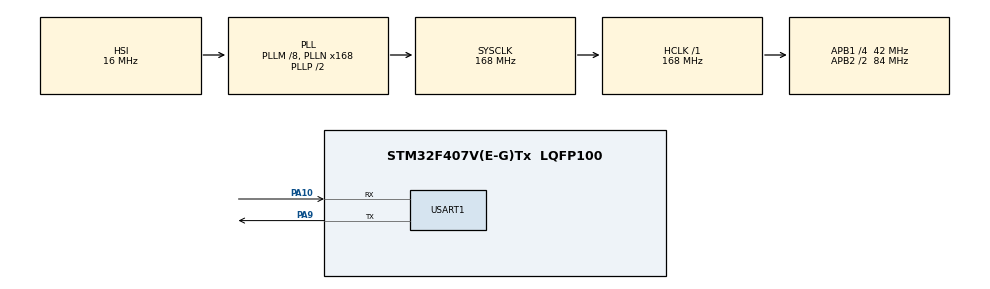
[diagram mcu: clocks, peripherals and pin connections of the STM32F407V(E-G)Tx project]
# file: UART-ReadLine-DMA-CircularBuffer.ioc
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Dma.Request0=USART1_RX
Dma.USART1_RX.0.Direction=DMA_PERIPH_TO_MEMORY
Dma.USART1_RX.0.FIFOMode=DMA_FIFOMODE_DISABLE
Dma.USART1_RX.0.Instance=DMA2_Stream2
Dma.USART1_RX.0.MemDataAlignment=DMA_MDATAALIGN_BYTE
Dma.USART1_RX.0.MemInc=DMA_MINC_ENABLE
Dma.USART1_RX.0.Mode=DMA_NORMAL
Dma.USART1_RX.0.PeriphDataAlignment=DMA_PDATAALIGN_BYTE
Dma.USART1_RX.0.PeriphInc=DMA_PINC_DISABLE
Dma.USART1_RX.0.Priority=DMA_PRIORITY_LOW
Mcu.Family=STM32F4
Mcu.Name=STM32F407V(E-G)Tx
Mcu.Package=LQFP100
NVIC.DMA2_Stream2_IRQn=true\:0\:0\:false\:false\:true\:false\:true
NVIC.PriorityGroup=NVIC_PRIORITYGROUP_4
NVIC.USART1_IRQn=true\:0\:0\:false\:false\:true\:true\:true
PA10.Mode=Asynchronous
PA10.Signal=USART1_RX
PA9.Mode=Asynchronous
PA9.Signal=USART1_TX
ProjectManager.HeapSize=0x200
ProjectManager.StackSize=0x400
ProjectManager.TargetToolchain=MDK-ARM V5.27
RCC.48MHZClocksFreq_Value=84000000
RCC.AHBFreq_Value=168000000
RCC.APB1CLKDivider=RCC_HCLK_DIV4
RCC.APB1Freq_Value=42000000
RCC.APB1TimFreq_Value=84000000
RCC.APB2CLKDivider=RCC_HCLK_DIV2
RCC.APB2Freq_Value=84000000
RCC.APB2TimFreq_Value=168000000
RCC.CortexFreq_Value=168000000
RCC.HCLKFreq_Value=168000000
RCC.HSE_VALUE=25000000
RCC.HSI_VALUE=16000000
RCC.LSE_VALUE=32768
RCC.PLLM=8
RCC.PLLN=168
RCC.SYSCLKFreq_VALUE=168000000
RCC.SYSCLKSource=RCC_SYSCLKSOURCE_PLLCLK
RCC.VCOOutputFreq_Value=336000000
USART1.VirtualMode=VM_ASYNC
board=custom

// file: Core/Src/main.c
/* USER CODE BEGIN Header */
/**
  ******************************************************************************
  * @file           : main.c
  * @brief          : Main program body
  ******************************************************************************
  * @attention
  *
  * <h2><center>&copy; Copyright (c) 2023 STMicroelectronics.
  * All rights reserved.</center></h2>
  *
  * This software component is licensed by ST under BSD 3-Clause license,
  * the "License"; You may not use this file except in compliance with the
  * License. You may obtain a copy of the License at:
  *                        opensource.org/licenses/BSD-3-Clause
  *
  ******************************************************************************
  */
/* USER CODE END Header */
#include "main.h"
#include "dma.h"
#include "usart.h"
#include "gpio.h"

/* USER CODE BEGIN Includes */
#include <string.h>
/* USER CODE END Includes */

/* USER CODE BEGIN PTD */

//                         Circular Buffer (FIFO)
//            Overflow 0                           Overflow 1
//  _______________________________   |  ________________________________
// |_______|_____________|_________|  | |_____|_________________|________|
// 0       R             W         S  | 0     W                 R        S
//
// R: RPos, W: WPos, S: Size, OVF: Overflow
//
// Formulas: Available (Read)
// OVF  R    W
//  0   R <  W   =>   W - R
//  1   R >  W   =>   S - R + W
//  0   R == W   =>   0
//  1   R == W   =>   S
//  Available = S * OVF + W - R
//
// Formulas: Space (Write)
// OVF  R    W
//  0   R <  W   =>   S - W + R
//  1   R >  W   =>   R - W
//  0   R == W   =>   S
//  1   R == W   =>   0
//  Space = S * !OVF + R - W

typedef enum {
  UART_CircularBuffer_Result_Ok,
  UART_CircularBuffer_Result_NoSpace,
  UART_CircularBuffer_Result_NoAvailable,
} UART_CircularBuffer_Result;

typedef struct {
  UART_HandleTypeDef*     HUART;
  uint8_t*                Buffer;
  int16_t                 WPos;
  int16_t                 RPos;
  int16_t                 Size;
  int16_t                 PendingBytes;
  uint8_t                 Overflow;
  uint8_t                 InReceive;
  uint8_t                 InTransmit;
} UART_CircularBuffer;

/* USER CODE END PTD */

/* USER CODE BEGIN PV */
static uint8_t uart1RxBuf[100];
static UART_CircularBuffer uart1Rx;
/* USER CODE END PV */

void SystemClock_Config(void);
/* USER CODE BEGIN PFP */
void UART_CircularBuffer_init(UART_CircularBuffer* buf, UART_HandleTypeDef* huart, uint8_t* dataBuf, int16_t size);

int16_t UART_CircularBuffer_available(UART_CircularBuffer* buf);
int16_t UART_CircularBuffer_space(UART_CircularBuffer* buf);

int16_t UART_CircularBuffer_availableUncheck(UART_CircularBuffer* buf);
int16_t UART_CircularBuffer_spaceUncheck(UART_CircularBuffer* buf);

UART_CircularBuffer_Result UART_CircularBuffer_writeBytes(UART_CircularBuffer* buf, uint8_t* data, uint32_t len);
UART_CircularBuffer_Result UART_CircularBuffer_readBytes(UART_CircularBuffer* buf, uint8_t* data, uint32_t len);

void UART_CircularBuffer_moveWritePos(UART_CircularBuffer* buf, int16_t step);
void UART_CircularBuffer_moveReadPos(UART_CircularBuffer* buf, int16_t step);

int16_t UART_CircularBuffer_directAvailable(UART_CircularBuffer* buf);
int16_t UART_CircularBuffer_directSpace(UART_CircularBuffer* buf);

uint8_t* UART_CircularBuffer_getReadDataPtr(UART_CircularBuffer* buf);
uint8_t* UART_CircularBuffer_getWriteDataPtr(UART_CircularBuffer* buf);

int16_t UART_CircularBuffer_findByte(UART_CircularBuffer* buf, uint8_t val);

// UART Rx APIs
void UART_CircularBuffer_receive(UART_CircularBuffer* buf);
void UART_CircularBuffer_handleRx(UART_CircularBuffer* buf);

/* USER CODE END PFP */

int main(void)
{

  /* MCU Configuration--------------------------------------------------------*/

  /* Reset of all peripherals, Initializes the Flash interface and the Systick. */
  HAL_Init();

  /* Configure the system clock */
  SystemClock_Config();

  /* Initialize all configured peripherals */
  MX_GPIO_Init();
  MX_DMA_Init();
  MX_USART1_UART_Init();
  /* USER CODE BEGIN 2 */
  UART_CircularBuffer_init(&uart1Rx, &huart1, uart1RxBuf, sizeof(uart1RxBuf));
  /* USER CODE END 2 */

  /* Infinite loop */
  /* USER CODE BEGIN WHILE */
  UART_CircularBuffer_receive(&uart1Rx);

  while (1)
  {
    if (UART_CircularBuffer_available(&uart1Rx) > 0) {
      int16_t len = UART_CircularBuffer_findByte(&uart1Rx, '\n');

      if (len > 0) {
        char temp[32];
        len++;

        UART_CircularBuffer_readBytes(&uart1Rx, (uint8_t*) temp, len);

        // Process
        HAL_UART_Transmit(&huart1, (uint8_t*) temp, len, len);
      }
    }
    /* USER CODE END WHILE */

  }
}

void SystemClock_Config(void)
{
  RCC_OscInitTypeDef RCC_OscInitStruct = {0};
  RCC_ClkInitTypeDef RCC_ClkInitStruct = {0};

  /** Configure the main internal regulator output voltage
  */
  __HAL_RCC_PWR_CLK_ENABLE();
  __HAL_PWR_VOLTAGESCALING_CONFIG(PWR_REGULATOR_VOLTAGE_SCALE1);
  /** Initializes the RCC Oscillators according to the specified parameters
  * in the RCC_OscInitTypeDef structure.
  */
  RCC_OscInitStruct.OscillatorType = RCC_OSCILLATORTYPE_HSI;
  RCC_OscInitStruct.HSIState = RCC_HSI_ON;
  RCC_OscInitStruct.HSICalibrationValue = RCC_HSICALIBRATION_DEFAULT;
  RCC_OscInitStruct.PLL.PLLState = RCC_PLL_ON;
  RCC_OscInitStruct.PLL.PLLSource = RCC_PLLSOURCE_HSI;
  RCC_OscInitStruct.PLL.PLLM = 8;
  RCC_OscInitStruct.PLL.PLLN = 168;
  RCC_OscInitStruct.PLL.PLLP = RCC_PLLP_DIV2;
  RCC_OscInitStruct.PLL.PLLQ = 4;
  if (HAL_RCC_OscConfig(&RCC_OscInitStruct) != HAL_OK)
  {
    Error_Handler();
  }
  /** Initializes the CPU, AHB and APB buses clocks
  */
  RCC_ClkInitStruct.ClockType = RCC_CLOCKTYPE_HCLK|RCC_CLOCKTYPE_SYSCLK
                              |RCC_CLOCKTYPE_PCLK1|RCC_CLOCKTYPE_PCLK2;
  RCC_ClkInitStruct.SYSCLKSource = RCC_SYSCLKSOURCE_PLLCLK;
  RCC_ClkInitStruct.AHBCLKDivider = RCC_SYSCLK_DIV1;
  RCC_ClkInitStruct.APB1CLKDivider = RCC_HCLK_DIV4;
  RCC_ClkInitStruct.APB2CLKDivider = RCC_HCLK_DIV2;

  if (HAL_RCC_ClockConfig(&RCC_ClkInitStruct, FLASH_LATENCY_5) != HAL_OK)
  {
    Error_Handler();
  }
}

/* USER CODE BEGIN 4 */
void HAL_UART_RxCpltCallback(UART_HandleTypeDef* huart) {
  switch ((uint32_t) huart->Instance) {
    case USART1_BASE:
      UART_CircularBuffer_handleRx(&uart1Rx);
      break;
    default:

      break;
  }
}

void UART_CircularBuffer_init(UART_CircularBuffer* buf, UART_HandleTypeDef* huart, uint8_t* dataBuf, int16_t size) {
  buf->HUART = huart;
  buf->Buffer = dataBuf;
  buf->Size = size;
  buf->Overflow = 0;
  buf->RPos = 0;
  buf->WPos = 0;
  buf->InReceive = 0;
  buf->InTransmit = 0;
}

int16_t UART_CircularBuffer_availableUncheck(UART_CircularBuffer* buf) {
  return buf->Size * buf->Overflow + buf->WPos - buf->RPos;
}
int16_t UART_CircularBuffer_spaceUncheck(UART_CircularBuffer* buf) {
  return buf->Size * (!buf->Overflow) + buf->RPos - buf->WPos;
}

int16_t UART_CircularBuffer_available(UART_CircularBuffer* buf) {
  int16_t bytesLen = buf->HUART->hdmarx ?
                      buf->PendingBytes - __HAL_DMA_GET_COUNTER(buf->HUART->hdmarx) :
                      buf->PendingBytes - buf->HUART->RxXferCount;

  if (bytesLen > 0) {
    UART_CircularBuffer_moveWritePos(buf, bytesLen);
    buf->PendingBytes -= bytesLen;
  }

  return UART_CircularBuffer_availableUncheck(buf);
}
int16_t UART_CircularBuffer_space(UART_CircularBuffer* buf) {
  int16_t bytesLen = buf->HUART->hdmatx ?
                      buf->PendingBytes - __HAL_DMA_GET_COUNTER(buf->HUART->hdmatx) :
                      buf->PendingBytes - buf->HUART->TxXferCount;

  if (bytesLen > 0) {
    UART_CircularBuffer_moveReadPos(buf, bytesLen);
    buf->PendingBytes -= bytesLen;
  }

  return UART_CircularBuffer_spaceUncheck(buf);
}

UART_CircularBuffer_Result UART_CircularBuffer_writeBytes(UART_CircularBuffer* buf, uint8_t* data, uint32_t len) {
  if (UART_CircularBuffer_space(buf) < len) {
    return UART_CircularBuffer_Result_NoSpace;
  }

  if (buf->WPos + len >= buf->Size) {
    int16_t tmpLen = buf->Size - buf->WPos;

    memcpy(&buf->Buffer[buf->WPos], data, tmpLen);
    data += tmpLen;
    len -= tmpLen;
    // buf->WPos = (buf->WPos + tmpLen) % buf->Size
    buf->WPos = 0;
    buf->Overflow = 1;
  }

  if (len > 0) {
    memcpy(&buf->Buffer[buf->WPos], data, len);
    buf->WPos += len;
  }

  return UART_CircularBuffer_Result_Ok;
}
UART_CircularBuffer_Result UART_CircularBuffer_readBytes(UART_CircularBuffer* buf, uint8_t* data, uint32_t len) {
  if (UART_CircularBuffer_available(buf) < len) {
    return UART_CircularBuffer_Result_NoAvailable;
  }

  if (buf->RPos + len >= buf->Size) {
    int16_t tmpLen = buf->Size - buf->RPos;

    memcpy(data, &buf->Buffer[buf->RPos], tmpLen);
    data += tmpLen;
    len -= tmpLen;
    // buf->RPos = (buf->RPos + tmpLen) % buf->Size
    buf->RPos = 0;
    buf->Overflow = 0;
  }

  if (len > 0) {
    memcpy(data, &buf->Buffer[buf->RPos], len);
    buf->RPos += len;
  }

  return UART_CircularBuffer_Result_Ok;
}
void UART_CircularBuffer_moveWritePos(UART_CircularBuffer* buf, int16_t step) {
  buf->WPos += step;
  if (buf->WPos >= buf->Size) {
    buf->WPos = 0;
    buf->Overflow = 1;
  }
}

void UART_CircularBuffer_moveReadPos(UART_CircularBuffer* buf, int16_t step) {
  buf->RPos += step;
  if (buf->RPos >= buf->Size) {
    buf->RPos = 0;
    buf->Overflow = 0;
  }
}
int16_t UART_CircularBuffer_directAvailable(UART_CircularBuffer* buf) {
  return buf->Overflow ? buf->Size - buf->RPos :
                         buf->WPos - buf->RPos;
}
int16_t UART_CircularBuffer_directSpace(UART_CircularBuffer* buf) {
  return buf->Overflow ? buf->RPos - buf->WPos :
                         buf->Size - buf->WPos;
}
uint8_t* UART_CircularBuffer_getReadDataPtr(UART_CircularBuffer* buf) {
  return &buf->Buffer[buf->RPos];
}
uint8_t* UART_CircularBuffer_getWriteDataPtr(UART_CircularBuffer* buf) {
  return &buf->Buffer[buf->WPos];
}

int16_t UART_CircularBuffer_findByte(UART_CircularBuffer* buf, uint8_t val) {
  if (UART_CircularBuffer_available(buf) <= 0) {
    return -1;
  }

  int16_t offset = 0;
  int16_t len = UART_CircularBuffer_directAvailable(buf);
  uint8_t* base = UART_CircularBuffer_getReadDataPtr(buf);
  uint8_t* p = memchr(base, val, len);

  if (p == NULL && buf->Overflow) {
    offset = len;
    base = buf->Buffer;
    len = buf->WPos;
    p = memchr(base, val, len);
  }

  return p == NULL ? -1 : (int16_t)(p - base) + offset;
}

// --------------------- UART Rx APIs --------------------------
void UART_CircularBuffer_receive(UART_CircularBuffer* buf) {
  if (!buf->InReceive) {
    buf->PendingBytes = UART_CircularBuffer_directSpace(buf);
    if (buf->PendingBytes > 0) {
      buf->InReceive = 1;
      // Check IT or DMA
      if (buf->HUART->hdmarx) {
        HAL_UART_Receive_DMA(
            buf->HUART,
            UART_CircularBuffer_getWriteDataPtr(buf),
            buf->PendingBytes
        );
      }
      else {
        HAL_UART_Receive_IT(
            buf->HUART,
            UART_CircularBuffer_getWriteDataPtr(buf),
            buf->PendingBytes
        );
      }
    }
  }
}
void UART_CircularBuffer_handleRx(UART_CircularBuffer* buf) {
  if (buf->InReceive) {
    buf->InReceive = 0;
    UART_CircularBuffer_moveWritePos(buf, buf->PendingBytes);
    UART_CircularBuffer_receive(buf);
  }
}

/* USER CODE END 4 */

void Error_Handler(void)
{
  __disable_irq();
  while (1)
  {
  }
}

/************************ (C) COPYRIGHT STMicroelectronics *****END OF FILE****/
